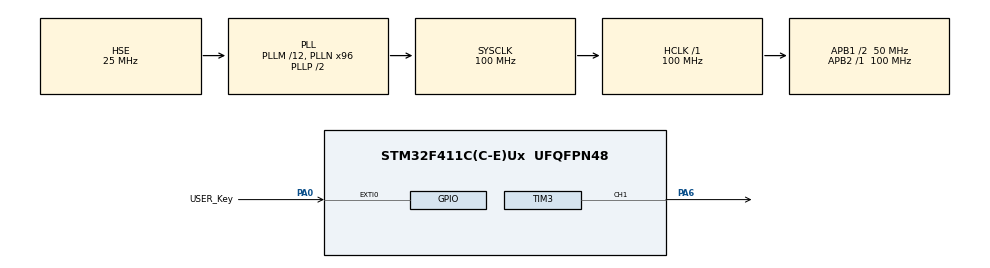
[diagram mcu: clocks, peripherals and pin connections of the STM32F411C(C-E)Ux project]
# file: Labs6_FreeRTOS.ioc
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Mcu.Family=STM32F4
Mcu.Name=STM32F411C(C-E)Ux
Mcu.Package=UFQFPN48
NVIC.EXTI0_IRQn=true\:0\:0\:false\:false\:true\:true\:true\:true
NVIC.PriorityGroup=NVIC_PRIORITYGROUP_4
PA0-WKUP.GPIO_Label=USER_Key
PA0-WKUP.GPIO_ModeDefaultEXTI=GPIO_MODE_IT_FALLING
PA0-WKUP.GPIO_PuPd=GPIO_PULLUP
PA0-WKUP.Signal=GPXTI0
PA6.Signal=S_TIM3_CH1
PH0\ -\ OSC_IN.Mode=HSE-External-Oscillator
PH0\ -\ OSC_IN.Signal=RCC_OSC_IN
PH1\ -\ OSC_OUT.Mode=HSE-External-Oscillator
PH1\ -\ OSC_OUT.Signal=RCC_OSC_OUT
ProjectManager.HeapSize=0x200
ProjectManager.StackSize=0x400
ProjectManager.TargetToolchain=STM32CubeIDE
RCC.48MHZClocksFreq_Value=50000000
RCC.AHBFreq_Value=100000000
RCC.APB1CLKDivider=RCC_HCLK_DIV2
RCC.APB1Freq_Value=50000000
RCC.APB1TimFreq_Value=100000000
RCC.APB2Freq_Value=100000000
RCC.APB2TimFreq_Value=100000000
RCC.CortexFreq_Value=100000000
RCC.HCLKFreq_Value=100000000
RCC.HSE_VALUE=25000000
RCC.HSI_VALUE=16000000
RCC.LSE_VALUE=32768
RCC.PLLM=12
RCC.PLLN=96
RCC.PLLSourceVirtual=RCC_PLLSOURCE_HSE
RCC.SYSCLKFreq_VALUE=100000000
RCC.SYSCLKSource=RCC_SYSCLKSOURCE_PLLCLK
RCC.VCOOutputFreq_Value=200000000
SH.S_TIM3_CH1.0=TIM3_CH1,PWM Generation1 CH1
TIM3.AutoReloadPreload=TIM_AUTORELOAD_PRELOAD_ENABLE
TIM3.Channel-PWM\ Generation1\ CH1=TIM_CHANNEL_1
TIM3.Period=1999
TIM3.Prescaler=99
TIM3.Pulse-PWM\ Generation1\ CH1=200
board=custom

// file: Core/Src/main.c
/* USER CODE BEGIN Header */

/*Лабораторна робота 6.
Широтно-імпульсна модуляція для управління силовими
елементами на основі апаратних таймерів.*/

/* Підключення: 1 GND - [-LED+] - [резистор 325R] - PA6 (HAL_TIM_PWM_ConfigChannel(&htim3, &sConfigOC, TIM_CHANNEL_1))
 *              2 GND - [-Key+] - [резистор 330R] - PA0
 * */

/* USER CODE END Header */
#include "main.h"

TIM_HandleTypeDef htim3;

/* USER CODE BEGIN PV */

uint32_t duty_percent = 10; // Поточний відсоток
const uint32_t period_val = 2000; // Наш ARR + 1

/* USER CODE END PV */

void SystemClock_Config(void);
static void MX_GPIO_Init(void);
static void MX_TIM3_Init(void);

/* USER CODE BEGIN 0 */

void HAL_GPIO_EXTI_Callback(uint16_t GPIO_Pin)
{
    if (GPIO_Pin == USER_Key_Pin) // Перевіряємо, що спрацювала саме кнопка
    {
        // Простий програмний антидребезг
        static uint32_t last_tick = 0;
        if (HAL_GetTick() - last_tick < 200) return;
        last_tick = HAL_GetTick();

        // Логіка зміни duty cycle: 10% -> 30% -> 50% -> 70% -> 90% -> 10%
        duty_percent += 20;
        if (duty_percent > 90) {
            duty_percent = 10;
        }

        // Оновлюємо значення в регістрі таймера (апаратна зміна)
        uint32_t new_pulse = (duty_percent * period_val) / 100;
        __HAL_TIM_SET_COMPARE(&htim3, TIM_CHANNEL_1, new_pulse);
    }
}

/* USER CODE END 0 */

int main(void)
{

  /* MCU Configuration--------------------------------------------------------*/

  /* Reset of all peripherals, Initializes the Flash interface and the Systick. */
  HAL_Init();

  /* Configure the system clock */
  SystemClock_Config();

  /* Initialize all configured peripherals */
  MX_GPIO_Init();
  MX_TIM3_Init();
  /* USER CODE BEGIN 2 */
  HAL_TIM_PWM_Start(&htim3, TIM_CHANNEL_1); // Запускаємо PWM
  /* USER CODE END 2 */

  /* Infinite loop */
  while (1)
  {

  }
}

void SystemClock_Config(void)
{
  RCC_OscInitTypeDef RCC_OscInitStruct = {0};
  RCC_ClkInitTypeDef RCC_ClkInitStruct = {0};

  /** Configure the main internal regulator output voltage
  */
  __HAL_RCC_PWR_CLK_ENABLE();
  __HAL_PWR_VOLTAGESCALING_CONFIG(PWR_REGULATOR_VOLTAGE_SCALE1);

  /** Initializes the RCC Oscillators according to the specified parameters
  * in the RCC_OscInitTypeDef structure.
  */
  RCC_OscInitStruct.OscillatorType = RCC_OSCILLATORTYPE_HSE;
  RCC_OscInitStruct.HSEState = RCC_HSE_ON;
  RCC_OscInitStruct.PLL.PLLState = RCC_PLL_ON;
  RCC_OscInitStruct.PLL.PLLSource = RCC_PLLSOURCE_HSE;
  RCC_OscInitStruct.PLL.PLLM = 12;
  RCC_OscInitStruct.PLL.PLLN = 96;
  RCC_OscInitStruct.PLL.PLLP = RCC_PLLP_DIV2;
  RCC_OscInitStruct.PLL.PLLQ = 4;
  if (HAL_RCC_OscConfig(&RCC_OscInitStruct) != HAL_OK)
  {
    Error_Handler();
  }

  /** Initializes the CPU, AHB and APB buses clocks
  */
  RCC_ClkInitStruct.ClockType = RCC_CLOCKTYPE_HCLK|RCC_CLOCKTYPE_SYSCLK
                              |RCC_CLOCKTYPE_PCLK1|RCC_CLOCKTYPE_PCLK2;
  RCC_ClkInitStruct.SYSCLKSource = RCC_SYSCLKSOURCE_PLLCLK;
  RCC_ClkInitStruct.AHBCLKDivider = RCC_SYSCLK_DIV1;
  RCC_ClkInitStruct.APB1CLKDivider = RCC_HCLK_DIV2;
  RCC_ClkInitStruct.APB2CLKDivider = RCC_HCLK_DIV1;

  if (HAL_RCC_ClockConfig(&RCC_ClkInitStruct, FLASH_LATENCY_3) != HAL_OK)
  {
    Error_Handler();
  }
}

static void MX_TIM3_Init(void)
{

  TIM_MasterConfigTypeDef sMasterConfig = {0};
  TIM_OC_InitTypeDef sConfigOC = {0};

  htim3.Instance = TIM3;
  htim3.Init.Prescaler = 99;
  htim3.Init.CounterMode = TIM_COUNTERMODE_UP;
  htim3.Init.Period = 1999;
  htim3.Init.ClockDivision = TIM_CLOCKDIVISION_DIV1;
  htim3.Init.AutoReloadPreload = TIM_AUTORELOAD_PRELOAD_ENABLE;
  if (HAL_TIM_PWM_Init(&htim3) != HAL_OK)
  {
    Error_Handler();
  }
  sMasterConfig.MasterOutputTrigger = TIM_TRGO_RESET;
  sMasterConfig.MasterSlaveMode = TIM_MASTERSLAVEMODE_DISABLE;
  if (HAL_TIMEx_MasterConfigSynchronization(&htim3, &sMasterConfig) != HAL_OK)
  {
    Error_Handler();
  }
  sConfigOC.OCMode = TIM_OCMODE_PWM1;
  sConfigOC.Pulse = 200;
  sConfigOC.OCPolarity = TIM_OCPOLARITY_HIGH;
  sConfigOC.OCFastMode = TIM_OCFAST_DISABLE;
  if (HAL_TIM_PWM_ConfigChannel(&htim3, &sConfigOC, TIM_CHANNEL_1) != HAL_OK)
  {
    Error_Handler();
  }
  HAL_TIM_MspPostInit(&htim3);

}

static void MX_GPIO_Init(void)
{
  GPIO_InitTypeDef GPIO_InitStruct = {0};

  /* GPIO Ports Clock Enable */
  __HAL_RCC_GPIOH_CLK_ENABLE();
  __HAL_RCC_GPIOA_CLK_ENABLE();

  /*Configure GPIO pin : USER_Key_Pin */
  GPIO_InitStruct.Pin = USER_Key_Pin;
  GPIO_InitStruct.Mode = GPIO_MODE_IT_FALLING;
  GPIO_InitStruct.Pull = GPIO_PULLUP;
  HAL_GPIO_Init(USER_Key_GPIO_Port, &GPIO_InitStruct);

  /* EXTI interrupt init*/
  HAL_NVIC_SetPriority(EXTI0_IRQn, 0, 0);
  HAL_NVIC_EnableIRQ(EXTI0_IRQn);

}

void Error_Handler(void)
{
  __disable_irq();
  while (1)
  {
  }
}
